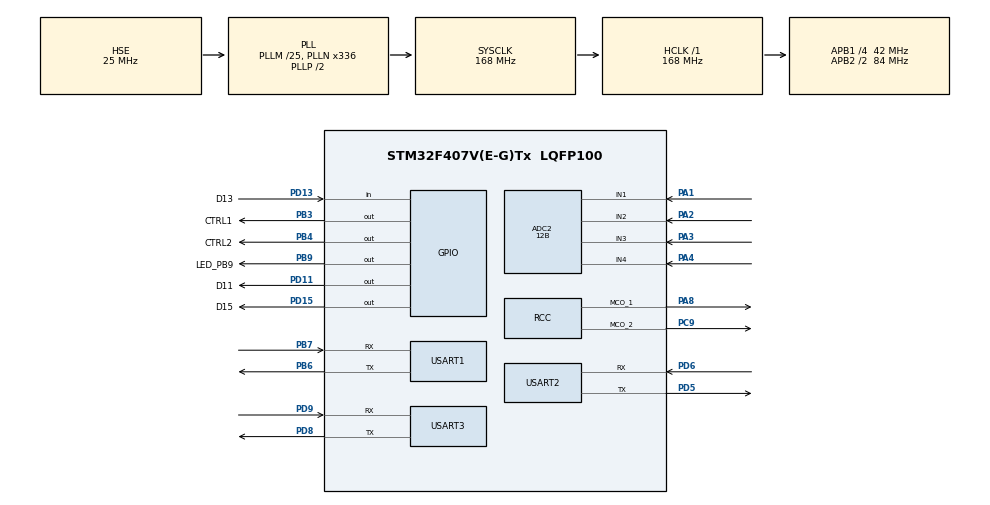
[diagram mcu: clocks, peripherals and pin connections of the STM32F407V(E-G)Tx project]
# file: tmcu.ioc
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ADC1.Channel-0\#ChannelRegularConversion=ADC_CHANNEL_TEMPSENSOR
ADC1.Channel-1\#ChannelInjectedConversion=ADC_CHANNEL_TEMPSENSOR
ADC1.Channel-2\#ChannelInjectedConversion=ADC_CHANNEL_VREFINT
ADC1.Channel-3\#ChannelInjectedConversion=ADC_CHANNEL_VBAT
ADC1.Channel-5\#ChannelInjectedConversion=ADC_CHANNEL_4
ADC1.ClockPrescaler=ADC_CLOCK_SYNC_PCLK_DIV8
ADC1.EOCSelection=ADC_EOC_SEQ_CONV
ADC1.ExternalTrigInjecConv=ADC_INJECTED_SOFTWARE_START
ADC1.InjNumberOfConversion=4
ADC1.InjectedConvMode=None
ADC1.InjectedOffset-1\#ChannelInjectedConversion=0
ADC1.InjectedOffset-2\#ChannelInjectedConversion=0
ADC1.InjectedOffset-3\#ChannelInjectedConversion=0
ADC1.InjectedOffset-5\#ChannelInjectedConversion=0
ADC1.NbrOfConversion=1
ADC1.NbrOfConversionFlag=1
ADC1.Rank-0\#ChannelRegularConversion=1
ADC1.Rank-1\#ChannelInjectedConversion=1
ADC1.Rank-2\#ChannelInjectedConversion=2
ADC1.Rank-3\#ChannelInjectedConversion=3
ADC1.Rank-5\#ChannelInjectedConversion=4
ADC1.SamplingTime-0\#ChannelRegularConversion=ADC_SAMPLETIME_3CYCLES
ADC1.SamplingTime-1\#ChannelInjectedConversion=ADC_SAMPLETIME_144CYCLES
ADC1.SamplingTime-2\#ChannelInjectedConversion=ADC_SAMPLETIME_144CYCLES
ADC1.SamplingTime-3\#ChannelInjectedConversion=ADC_SAMPLETIME_144CYCLES
ADC1.SamplingTime-5\#ChannelInjectedConversion=ADC_SAMPLETIME_144CYCLES
ADC1.ScanConvMode=ENABLE
ADC1.master=1
ADC2.Channel-4\#ChannelRegularConversion=ADC_CHANNEL_1
ADC2.Channel-5\#ChannelInjectedConversion=ADC_CHANNEL_1
ADC2.Channel-6\#ChannelInjectedConversion=ADC_CHANNEL_2
ADC2.Channel-7\#ChannelInjectedConversion=ADC_CHANNEL_3
ADC2.Channel-8\#ChannelInjectedConversion=ADC_CHANNEL_4
ADC2.ClockPrescaler=ADC_CLOCK_SYNC_PCLK_DIV8
ADC2.ContinuousConvMode=DISABLE
ADC2.DMAContinuousRequests=DISABLE
ADC2.DataAlign=ADC_DATAALIGN_RIGHT
ADC2.DiscontinuousConvMode=DISABLE
ADC2.EOCSelection=ADC_EOC_SEQ_CONV
ADC2.EnableAnalogWatchDog=false
ADC2.ExternalTrigConv=ADC_SOFTWARE_START
ADC2.ExternalTrigConvEdge=ADC_EXTERNALTRIGCONVEDGE_NONE
ADC2.ExternalTrigInjecConv=ADC_EXTERNALTRIGINJECCONV_T5_TRGO
ADC2.ExternalTrigInjecConvEdge=ADC_EXTERNALTRIGINJECCONVEDGE_RISING
ADC2.InjNumberOfConversion=4
ADC2.InjectedConvMode=None
ADC2.InjectedOffset-5\#ChannelInjectedConversion=0
ADC2.InjectedOffset-6\#ChannelInjectedConversion=0
ADC2.InjectedOffset-7\#ChannelInjectedConversion=0
ADC2.InjectedOffset-8\#ChannelInjectedConversion=0
ADC2.NbrOfConversion=1
ADC2.NbrOfConversionFlag=1
ADC2.Rank-4\#ChannelRegularConversion=1
ADC2.Rank-5\#ChannelInjectedConversion=1
ADC2.Rank-6\#ChannelInjectedConversion=2
ADC2.Rank-7\#ChannelInjectedConversion=3
ADC2.Rank-8\#ChannelInjectedConversion=4
ADC2.Resolution=ADC_RESOLUTION_12B
ADC2.SamplingTime-4\#ChannelRegularConversion=ADC_SAMPLETIME_3CYCLES
ADC2.SamplingTime-5\#ChannelInjectedConversion=ADC_SAMPLETIME_15CYCLES
ADC2.SamplingTime-6\#ChannelInjectedConversion=ADC_SAMPLETIME_15CYCLES
ADC2.SamplingTime-7\#ChannelInjectedConversion=ADC_SAMPLETIME_15CYCLES
ADC2.SamplingTime-8\#ChannelInjectedConversion=ADC_SAMPLETIME_15CYCLES
ADC2.ScanConvMode=ENABLE
IWDG.Prescaler=IWDG_PRESCALER_32
IWDG.Reload=2000
Mcu.Family=STM32F4
Mcu.Name=STM32F407V(E-G)Tx
Mcu.Package=LQFP100
NVIC.ADC_IRQn=true\:6\:0\:true\:false\:true
NVIC.PriorityGroup=NVIC_PRIORITYGROUP_3
NVIC.TIM5_IRQn=true\:4\:0\:true\:false\:true
NVIC.TIM6_DAC_IRQn=true\:5\:0\:true\:false\:true
NVIC.TIM7_IRQn=true\:4\:0\:true\:false\:true
NVIC.USART1_IRQn=true\:7\:0\:true\:false\:true
NVIC.USART2_IRQn=true\:7\:0\:true\:false\:true
NVIC.USART3_IRQn=true\:7\:0\:true\:false\:true
PA1.Signal=ADCx_IN1
PA2.Signal=ADCx_IN2
PA3.Signal=ADCx_IN3
PA4.Signal=ADCx_IN4
PA8.Mode=Clock-out-1
PA8.Signal=RCC_MCO_1
PB3.GPIO_Label=CTRL1
PB3.Signal=GPIO_Output
PB4.GPIO_Label=CTRL2
PB4.Signal=GPIO_Output
PB6.Mode=Asynchronous
PB6.Signal=USART1_TX
PB7.Mode=Asynchronous
PB7.Signal=USART1_RX
PB9.GPIO_Label=LED_PB9
PB9.Signal=GPIO_Output
PC9.Mode=Clock-out-2
PC9.Signal=RCC_MCO_2
PD11.GPIO_Label=D11
PD11.Signal=GPIO_Output
PD13.GPIO_Label=D13
PD13.Signal=GPIO_Input
PD15.GPIO_Label=D15
PD15.Signal=GPIO_Output
PD5.Mode=Asynchronous
PD5.Signal=USART2_TX
PD6.Mode=Asynchronous
PD6.Signal=USART2_RX
PD8.Mode=Asynchronous
PD8.Signal=USART3_TX
PD9.Mode=Asynchronous
PD9.Signal=USART3_RX
PH0-OSC_IN.Mode=HSE-External-Oscillator
PH0-OSC_IN.Signal=RCC_OSC_IN
PH1-OSC_OUT.Mode=HSE-External-Oscillator
PH1-OSC_OUT.Signal=RCC_OSC_OUT
ProjectManager.HeapSize=0x200
ProjectManager.StackSize=0x400
ProjectManager.TargetToolchain=MDK-ARM V5
RCC.48MHZClocksFreq_Value=48000000
RCC.AHBFreq_Value=168000000
RCC.APB1CLKDivider=RCC_HCLK_DIV4
RCC.APB1Freq_Value=42000000
RCC.APB1TimFreq_Value=84000000
RCC.APB2CLKDivider=RCC_HCLK_DIV2
RCC.APB2Freq_Value=84000000
RCC.APB2TimFreq_Value=168000000
RCC.CortexFreq_Value=168000000
RCC.HCLKFreq_Value=168000000
RCC.HSE_VALUE=25000000
RCC.HSI_VALUE=16000000
RCC.LSE_VALUE=32768
RCC.PLLM=25
RCC.PLLN=336
RCC.PLLQ=7
RCC.PLLSourceVirtual=RCC_PLLSOURCE_HSE
RCC.SYSCLKFreq_VALUE=168000000
RCC.SYSCLKSource=RCC_SYSCLKSOURCE_PLLCLK
RCC.VCOOutputFreq_Value=336000000
SH.ADCx_IN1.0=ADC2_IN1,IN1
SH.ADCx_IN2.0=ADC2_IN2,IN2
SH.ADCx_IN3.0=ADC2_IN3,IN3
SH.ADCx_IN4.0=ADC2_IN4,IN4
SH.ADCx_IN4.1=ADC1_IN4,IN4
TIM5.Period=125
TIM5.Prescaler=83
TIM5.TIM_MasterOutputTrigger=TIM_TRGO_UPDATE
TIM6.Period=10000
TIM6.Prescaler=8399
TIM6.TIM_MasterOutputTrigger=TIM_TRGO_UPDATE
TIM7.Period=1000
TIM7.Prescaler=8399
TIM7.TIM_MasterOutputTrigger=TIM_TRGO_UPDATE
USART1.VirtualMode=VM_ASYNC
USART2.VirtualMode=VM_ASYNC
USART3.VirtualMode=VM_ASYNC
VP_ADC1_TempSens_Input.Mode=IN-TempSens
VP_ADC1_Vbat_Input.Mode=IN-Vbat
VP_ADC1_Vref_Input.Mode=IN-Vrefint
VP_IWDG_VS_IWDG.Mode=IWDG_Activate
VP_RNG_VS_RNG.Mode=RNG_Activate
VP_TIM5_VS_ClockSourceINT.Mode=Internal
VP_TIM6_VS_ClockSourceINT.Mode=Enable_Timer
VP_TIM7_VS_ClockSourceINT.Mode=Enable_Timer
board=tmcu

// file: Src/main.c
/**
  ******************************************************************************
  * File Name          : main.c
  * Description        : Main program body
  ******************************************************************************
  ** This notice applies to any and all portions of this file
  * that are not between comment pairs USER CODE BEGIN and
  * USER CODE END. Other portions of this file, whether
  * inserted by the user or by software development tools
  * are owned by their respective copyright owners.
  *
  * COPYRIGHT(c) 2018 STMicroelectronics
  *
  * Redistribution and use in source and binary forms, with or without modification,
  * are permitted provided that the following conditions are met:
  *   1. Redistributions of source code must retain the above copyright notice,
  *      this list of conditions and the following disclaimer.
  *   2. Redistributions in binary form must reproduce the above copyright notice,
  *      this list of conditions and the following disclaimer in the documentation
  *      and/or other materials provided with the distribution.
  *   3. Neither the name of STMicroelectronics nor the names of its contributors
  *      may be used to endorse or promote products derived from this software
  *      without specific prior written permission.
  *
  * THIS SOFTWARE IS PROVIDED BY THE COPYRIGHT HOLDERS AND CONTRIBUTORS "AS IS"
  * AND ANY EXPRESS OR IMPLIED WARRANTIES, INCLUDING, BUT NOT LIMITED TO, THE
  * IMPLIED WARRANTIES OF MERCHANTABILITY AND FITNESS FOR A PARTICULAR PURPOSE ARE
  * DISCLAIMED. IN NO EVENT SHALL THE COPYRIGHT HOLDER OR CONTRIBUTORS BE LIABLE
  * FOR ANY DIRECT, INDIRECT, INCIDENTAL, SPECIAL, EXEMPLARY, OR CONSEQUENTIAL
  * DAMAGES (INCLUDING, BUT NOT LIMITED TO, PROCUREMENT OF SUBSTITUTE GOODS OR
  * SERVICES; LOSS OF USE, DATA, OR PROFITS; OR BUSINESS INTERRUPTION) HOWEVER
  * CAUSED AND ON ANY THEORY OF LIABILITY, WHETHER IN CONTRACT, STRICT LIABILITY,
  * OR TORT (INCLUDING NEGLIGENCE OR OTHERWISE) ARISING IN ANY WAY OUT OF THE USE
  * OF THIS SOFTWARE, EVEN IF ADVISED OF THE POSSIBILITY OF SUCH DAMAGE.
  *
  ******************************************************************************
  */
#include "main.h"
#include "stm32f4xx_hal.h"

/* USER CODE BEGIN Includes */
#include "action.h"
/* USER CODE END Includes */

ADC_HandleTypeDef hadc1;
ADC_HandleTypeDef hadc2;

IWDG_HandleTypeDef hiwdg;

RNG_HandleTypeDef hrng;

TIM_HandleTypeDef htim5;
TIM_HandleTypeDef htim6;
TIM_HandleTypeDef htim7;

UART_HandleTypeDef huart1;
UART_HandleTypeDef huart2;
UART_HandleTypeDef huart3;

/* USER CODE BEGIN PV */
/* Private variables ---------------------------------------------------------*/

/* USER CODE END PV */

void SystemClock_Config(void);
static void MX_GPIO_Init(void);
static void MX_ADC1_Init(void);
static void MX_ADC2_Init(void);
static void MX_IWDG_Init(void);
static void MX_RNG_Init(void);
static void MX_TIM5_Init(void);
static void MX_TIM6_Init(void);
static void MX_TIM7_Init(void);
static void MX_USART1_UART_Init(void);
static void MX_USART2_UART_Init(void);
static void MX_USART3_UART_Init(void);

/* USER CODE BEGIN PFP */
/* Private function prototypes -----------------------------------------------*/

/* USER CODE END PFP */

int main(void)
{

  /* MCU Configuration----------------------------------------------------------*/

  /* Reset of all peripherals, Initializes the Flash interface and the Systick. */
  HAL_Init();

  /* Configure the system clock */
  SystemClock_Config();

  /* Initialize all configured peripherals */
  MX_GPIO_Init();
  MX_ADC1_Init();
  MX_ADC2_Init();
//  MX_IWDG_Init();
  MX_RNG_Init();
  MX_TIM5_Init();
  MX_TIM6_Init();
  MX_TIM7_Init();
  MX_USART1_UART_Init();
  MX_USART2_UART_Init();
  MX_USART3_UART_Init();

  /* USER CODE BEGIN 2 */
	App_Init();
  /* USER CODE END 2 */

  /* Infinite loop */
  while (1)
  {
	App_Action();
  }

}

/** System Clock Configuration
*/
void SystemClock_Config(void)
{

  RCC_OscInitTypeDef RCC_OscInitStruct;
  RCC_ClkInitTypeDef RCC_ClkInitStruct;

    /**Configure the main internal regulator output voltage
    */
  __HAL_RCC_PWR_CLK_ENABLE();

  __HAL_PWR_VOLTAGESCALING_CONFIG(PWR_REGULATOR_VOLTAGE_SCALE1);

    /**Initializes the CPU, AHB and APB busses clocks
    */
  RCC_OscInitStruct.OscillatorType = RCC_OSCILLATORTYPE_HSI|RCC_OSCILLATORTYPE_LSI
                              |RCC_OSCILLATORTYPE_HSE;
  RCC_OscInitStruct.HSEState = RCC_HSE_ON;
  RCC_OscInitStruct.HSIState = RCC_HSI_ON;
  RCC_OscInitStruct.HSICalibrationValue = 16;
  RCC_OscInitStruct.LSIState = RCC_LSI_ON;
  RCC_OscInitStruct.PLL.PLLState = RCC_PLL_ON;
  RCC_OscInitStruct.PLL.PLLSource = RCC_PLLSOURCE_HSE;
  RCC_OscInitStruct.PLL.PLLM = 25;
  RCC_OscInitStruct.PLL.PLLN = 336;
  RCC_OscInitStruct.PLL.PLLP = RCC_PLLP_DIV2;
  RCC_OscInitStruct.PLL.PLLQ = 7;
  if (HAL_RCC_OscConfig(&RCC_OscInitStruct) != HAL_OK)
  {
    _Error_Handler(__FILE__, __LINE__);
  }

    /**Initializes the CPU, AHB and APB busses clocks
    */
  RCC_ClkInitStruct.ClockType = RCC_CLOCKTYPE_HCLK|RCC_CLOCKTYPE_SYSCLK
                              |RCC_CLOCKTYPE_PCLK1|RCC_CLOCKTYPE_PCLK2;
  RCC_ClkInitStruct.SYSCLKSource = RCC_SYSCLKSOURCE_PLLCLK;
  RCC_ClkInitStruct.AHBCLKDivider = RCC_SYSCLK_DIV1;
  RCC_ClkInitStruct.APB1CLKDivider = RCC_HCLK_DIV4;
  RCC_ClkInitStruct.APB2CLKDivider = RCC_HCLK_DIV2;

  if (HAL_RCC_ClockConfig(&RCC_ClkInitStruct, FLASH_LATENCY_5) != HAL_OK)
  {
    _Error_Handler(__FILE__, __LINE__);
  }

  HAL_RCC_MCOConfig(RCC_MCO1, RCC_MCO1SOURCE_HSI, RCC_MCODIV_1);

  HAL_RCC_MCOConfig(RCC_MCO2, RCC_MCO2SOURCE_SYSCLK, RCC_MCODIV_1);

    /**Configure the Systick interrupt time
    */
  HAL_SYSTICK_Config(HAL_RCC_GetHCLKFreq()/1000);

    /**Configure the Systick
    */
  HAL_SYSTICK_CLKSourceConfig(SYSTICK_CLKSOURCE_HCLK);

  /* SysTick_IRQn interrupt configuration */
  HAL_NVIC_SetPriority(SysTick_IRQn, 0, 0);
}

/* ADC1 init function */
static void MX_ADC1_Init(void)
{

  ADC_ChannelConfTypeDef sConfig;
  ADC_InjectionConfTypeDef sConfigInjected;

    /**Configure the global features of the ADC (Clock, Resolution, Data Alignment and number of conversion)
    */
  hadc1.Instance = ADC1;
  hadc1.Init.ClockPrescaler = ADC_CLOCK_SYNC_PCLK_DIV8;
  hadc1.Init.Resolution = ADC_RESOLUTION_12B;
  hadc1.Init.ScanConvMode = ENABLE;
  hadc1.Init.ContinuousConvMode = DISABLE;
  hadc1.Init.DiscontinuousConvMode = DISABLE;
  hadc1.Init.ExternalTrigConvEdge = ADC_EXTERNALTRIGCONVEDGE_NONE;
  hadc1.Init.ExternalTrigConv = ADC_SOFTWARE_START;
  hadc1.Init.DataAlign = ADC_DATAALIGN_RIGHT;
  hadc1.Init.NbrOfConversion = 1;
  hadc1.Init.DMAContinuousRequests = DISABLE;
  hadc1.Init.EOCSelection = ADC_EOC_SEQ_CONV;
  if (HAL_ADC_Init(&hadc1) != HAL_OK)
  {
    _Error_Handler(__FILE__, __LINE__);
  }

    /**Configure for the selected ADC regular channel its corresponding rank in the sequencer and its sample time.
    */
  sConfig.Channel = ADC_CHANNEL_TEMPSENSOR;
  sConfig.Rank = 1;
  sConfig.SamplingTime = ADC_SAMPLETIME_3CYCLES;
  if (HAL_ADC_ConfigChannel(&hadc1, &sConfig) != HAL_OK)
  {
    _Error_Handler(__FILE__, __LINE__);
  }

    /**Configures for the selected ADC injected channel its corresponding rank in the sequencer and its sample time
    */
  sConfigInjected.InjectedChannel = ADC_CHANNEL_TEMPSENSOR;
  sConfigInjected.InjectedRank = 1;
  sConfigInjected.InjectedNbrOfConversion = 4;
  sConfigInjected.InjectedSamplingTime = ADC_SAMPLETIME_144CYCLES;
  sConfigInjected.ExternalTrigInjecConvEdge = ADC_EXTERNALTRIGINJECCONVEDGE_NONE;
  sConfigInjected.ExternalTrigInjecConv = ADC_INJECTED_SOFTWARE_START;
  sConfigInjected.AutoInjectedConv = DISABLE;
  sConfigInjected.InjectedDiscontinuousConvMode = DISABLE;
  sConfigInjected.InjectedOffset = 0;
  if (HAL_ADCEx_InjectedConfigChannel(&hadc1, &sConfigInjected) != HAL_OK)
  {
    _Error_Handler(__FILE__, __LINE__);
  }

    /**Configures for the selected ADC injected channel its corresponding rank in the sequencer and its sample time
    */
  sConfigInjected.InjectedChannel = ADC_CHANNEL_VREFINT;
  sConfigInjected.InjectedRank = 2;
  if (HAL_ADCEx_InjectedConfigChannel(&hadc1, &sConfigInjected) != HAL_OK)
  {
    _Error_Handler(__FILE__, __LINE__);
  }

    /**Configures for the selected ADC injected channel its corresponding rank in the sequencer and its sample time
    */
  sConfigInjected.InjectedChannel = ADC_CHANNEL_VBAT;
  sConfigInjected.InjectedRank = 3;
  if (HAL_ADCEx_InjectedConfigChannel(&hadc1, &sConfigInjected) != HAL_OK)
  {
    _Error_Handler(__FILE__, __LINE__);
  }

    /**Configures for the selected ADC injected channel its corresponding rank in the sequencer and its sample time
    */
  sConfigInjected.InjectedChannel = ADC_CHANNEL_4;
  sConfigInjected.InjectedRank = 4;
  if (HAL_ADCEx_InjectedConfigChannel(&hadc1, &sConfigInjected) != HAL_OK)
  {
    _Error_Handler(__FILE__, __LINE__);
  }

}

/* ADC2 init function */
static void MX_ADC2_Init(void)
{

  ADC_ChannelConfTypeDef sConfig;
  ADC_InjectionConfTypeDef sConfigInjected;

    /**Configure the global features of the ADC (Clock, Resolution, Data Alignment and number of conversion)
    */
  hadc2.Instance = ADC2;
  hadc2.Init.ClockPrescaler = ADC_CLOCK_SYNC_PCLK_DIV8;
  hadc2.Init.Resolution = ADC_RESOLUTION_12B;
  hadc2.Init.ScanConvMode = ENABLE;
  hadc2.Init.ContinuousConvMode = DISABLE;
  hadc2.Init.DiscontinuousConvMode = DISABLE;
  hadc2.Init.ExternalTrigConvEdge = ADC_EXTERNALTRIGCONVEDGE_NONE;
  hadc2.Init.ExternalTrigConv = ADC_SOFTWARE_START;
  hadc2.Init.DataAlign = ADC_DATAALIGN_RIGHT;
  hadc2.Init.NbrOfConversion = 1;
  hadc2.Init.DMAContinuousRequests = DISABLE;
  hadc2.Init.EOCSelection = ADC_EOC_SEQ_CONV;
  if (HAL_ADC_Init(&hadc2) != HAL_OK)
  {
    _Error_Handler(__FILE__, __LINE__);
  }

    /**Configure for the selected ADC regular channel its corresponding rank in the sequencer and its sample time.
    */
  sConfig.Channel = ADC_CHANNEL_1;
  sConfig.Rank = 1;
  sConfig.SamplingTime = ADC_SAMPLETIME_3CYCLES;
  if (HAL_ADC_ConfigChannel(&hadc2, &sConfig) != HAL_OK)
  {
    _Error_Handler(__FILE__, __LINE__);
  }

    /**Configures for the selected ADC injected channel its corresponding rank in the sequencer and its sample time
    */
  sConfigInjected.InjectedChannel = ADC_CHANNEL_1;
  sConfigInjected.InjectedRank = 1;
  sConfigInjected.InjectedNbrOfConversion = 4;
  sConfigInjected.InjectedSamplingTime = ADC_SAMPLETIME_15CYCLES;
  sConfigInjected.ExternalTrigInjecConvEdge = ADC_EXTERNALTRIGINJECCONVEDGE_RISING;
  sConfigInjected.ExternalTrigInjecConv = ADC_EXTERNALTRIGINJECCONV_T5_TRGO;
  sConfigInjected.AutoInjectedConv = DISABLE;
  sConfigInjected.InjectedDiscontinuousConvMode = DISABLE;
  sConfigInjected.InjectedOffset = 0;
  if (HAL_ADCEx_InjectedConfigChannel(&hadc2, &sConfigInjected) != HAL_OK)
  {
    _Error_Handler(__FILE__, __LINE__);
  }

    /**Configures for the selected ADC injected channel its corresponding rank in the sequencer and its sample time
    */
  sConfigInjected.InjectedChannel = ADC_CHANNEL_2;
  sConfigInjected.InjectedRank = 2;
  if (HAL_ADCEx_InjectedConfigChannel(&hadc2, &sConfigInjected) != HAL_OK)
  {
    _Error_Handler(__FILE__, __LINE__);
  }

    /**Configures for the selected ADC injected channel its corresponding rank in the sequencer and its sample time
    */
  sConfigInjected.InjectedChannel = ADC_CHANNEL_3;
  sConfigInjected.InjectedRank = 3;
  if (HAL_ADCEx_InjectedConfigChannel(&hadc2, &sConfigInjected) != HAL_OK)
  {
    _Error_Handler(__FILE__, __LINE__);
  }

    /**Configures for the selected ADC injected channel its corresponding rank in the sequencer and its sample time
    */
  sConfigInjected.InjectedChannel = ADC_CHANNEL_4;
  sConfigInjected.InjectedRank = 4;
  if (HAL_ADCEx_InjectedConfigChannel(&hadc2, &sConfigInjected) != HAL_OK)
  {
    _Error_Handler(__FILE__, __LINE__);
  }

}

/* IWDG init function */
static void MX_IWDG_Init(void)
{

  hiwdg.Instance = IWDG;
  hiwdg.Init.Prescaler = IWDG_PRESCALER_32;
  hiwdg.Init.Reload = 2000;
  if (HAL_IWDG_Init(&hiwdg) != HAL_OK)
  {
    _Error_Handler(__FILE__, __LINE__);
  }

}

/* RNG init function */
static void MX_RNG_Init(void)
{

  hrng.Instance = RNG;
  if (HAL_RNG_Init(&hrng) != HAL_OK)
  {
    _Error_Handler(__FILE__, __LINE__);
  }

}

/* TIM5 init function */
static void MX_TIM5_Init(void)
{

  TIM_ClockConfigTypeDef sClockSourceConfig;
  TIM_MasterConfigTypeDef sMasterConfig;

  htim5.Instance = TIM5;
  htim5.Init.Prescaler = 83;
  htim5.Init.CounterMode = TIM_COUNTERMODE_UP;
  htim5.Init.Period = 125;
  htim5.Init.ClockDivision = TIM_CLOCKDIVISION_DIV1;
  if (HAL_TIM_Base_Init(&htim5) != HAL_OK)
  {
    _Error_Handler(__FILE__, __LINE__);
  }

  sClockSourceConfig.ClockSource = TIM_CLOCKSOURCE_INTERNAL;
  if (HAL_TIM_ConfigClockSource(&htim5, &sClockSourceConfig) != HAL_OK)
  {
    _Error_Handler(__FILE__, __LINE__);
  }

  sMasterConfig.MasterOutputTrigger = TIM_TRGO_UPDATE;
  sMasterConfig.MasterSlaveMode = TIM_MASTERSLAVEMODE_DISABLE;
  if (HAL_TIMEx_MasterConfigSynchronization(&htim5, &sMasterConfig) != HAL_OK)
  {
    _Error_Handler(__FILE__, __LINE__);
  }

}

/* TIM6 init function */
static void MX_TIM6_Init(void)
{

  TIM_MasterConfigTypeDef sMasterConfig;

  htim6.Instance = TIM6;
  htim6.Init.Prescaler = 8399;
  htim6.Init.CounterMode = TIM_COUNTERMODE_UP;
  htim6.Init.Period = 10000;
  if (HAL_TIM_Base_Init(&htim6) != HAL_OK)
  {
    _Error_Handler(__FILE__, __LINE__);
  }

  sMasterConfig.MasterOutputTrigger = TIM_TRGO_UPDATE;
  sMasterConfig.MasterSlaveMode = TIM_MASTERSLAVEMODE_DISABLE;
  if (HAL_TIMEx_MasterConfigSynchronization(&htim6, &sMasterConfig) != HAL_OK)
  {
    _Error_Handler(__FILE__, __LINE__);
  }

}

/* TIM7 init function */
static void MX_TIM7_Init(void)
{

  TIM_MasterConfigTypeDef sMasterConfig;

  htim7.Instance = TIM7;
  htim7.Init.Prescaler = 8399;
  htim7.Init.CounterMode = TIM_COUNTERMODE_UP;
  htim7.Init.Period = 1000;
  if (HAL_TIM_Base_Init(&htim7) != HAL_OK)
  {
    _Error_Handler(__FILE__, __LINE__);
  }

  sMasterConfig.MasterOutputTrigger = TIM_TRGO_UPDATE;
  sMasterConfig.MasterSlaveMode = TIM_MASTERSLAVEMODE_DISABLE;
  if (HAL_TIMEx_MasterConfigSynchronization(&htim7, &sMasterConfig) != HAL_OK)
  {
    _Error_Handler(__FILE__, __LINE__);
  }

}

/* USART1 init function */
static void MX_USART1_UART_Init(void)
{

  huart1.Instance = USART1;
  huart1.Init.BaudRate = 115200;
  huart1.Init.WordLength = UART_WORDLENGTH_8B;
  huart1.Init.StopBits = UART_STOPBITS_1;
  huart1.Init.Parity = UART_PARITY_NONE;
  huart1.Init.Mode = UART_MODE_TX_RX;
  huart1.Init.HwFlowCtl = UART_HWCONTROL_NONE;
  huart1.Init.OverSampling = UART_OVERSAMPLING_16;
  if (HAL_UART_Init(&huart1) != HAL_OK)
  {
    _Error_Handler(__FILE__, __LINE__);
  }

}

/* USART2 init function */
static void MX_USART2_UART_Init(void)
{

  huart2.Instance = USART2;
  huart2.Init.BaudRate = 115200;
  huart2.Init.WordLength = UART_WORDLENGTH_8B;
  huart2.Init.StopBits = UART_STOPBITS_1;
  huart2.Init.Parity = UART_PARITY_NONE;
  huart2.Init.Mode = UART_MODE_TX_RX;
  huart2.Init.HwFlowCtl = UART_HWCONTROL_NONE;
  huart2.Init.OverSampling = UART_OVERSAMPLING_16;
  if (HAL_UART_Init(&huart2) != HAL_OK)
  {
    _Error_Handler(__FILE__, __LINE__);
  }

}

/* USART3 init function */
static void MX_USART3_UART_Init(void)
{

  huart3.Instance = USART3;
  huart3.Init.BaudRate = 115200;
  huart3.Init.WordLength = UART_WORDLENGTH_8B;
  huart3.Init.StopBits = UART_STOPBITS_1;
  huart3.Init.Parity = UART_PARITY_NONE;
  huart3.Init.Mode = UART_MODE_TX_RX;
  huart3.Init.HwFlowCtl = UART_HWCONTROL_NONE;
  huart3.Init.OverSampling = UART_OVERSAMPLING_16;
  if (HAL_UART_Init(&huart3) != HAL_OK)
  {
    _Error_Handler(__FILE__, __LINE__);
  }

}

/** Configure pins as
        * Analog
        * Input
        * Output
        * EVENT_OUT
        * EXTI
     PC9   ------> RCC_MCO_2
     PA8   ------> RCC_MCO_1
*/
static void MX_GPIO_Init(void)
{

  GPIO_InitTypeDef GPIO_InitStruct;

  /* GPIO Ports Clock Enable */
  __HAL_RCC_GPIOH_CLK_ENABLE();
  __HAL_RCC_GPIOA_CLK_ENABLE();
  __HAL_RCC_GPIOD_CLK_ENABLE();
  __HAL_RCC_GPIOC_CLK_ENABLE();
  __HAL_RCC_GPIOB_CLK_ENABLE();

  /*Configure GPIO pin Output Level */
  HAL_GPIO_WritePin(GPIOD, D11_Pin|D15_Pin, GPIO_PIN_RESET);

  /*Configure GPIO pin Output Level */
  HAL_GPIO_WritePin(GPIOB, CTRL1_Pin|CTRL2_Pin|LED_PB9_Pin, GPIO_PIN_RESET);

  /*Configure GPIO pins : D11_Pin D15_Pin */
  GPIO_InitStruct.Pin = D11_Pin|D15_Pin;
  GPIO_InitStruct.Mode = GPIO_MODE_OUTPUT_PP;
  GPIO_InitStruct.Pull = GPIO_NOPULL;
  GPIO_InitStruct.Speed = GPIO_SPEED_FREQ_LOW;
  HAL_GPIO_Init(GPIOD, &GPIO_InitStruct);

  /*Configure GPIO pin : D13_Pin */
  GPIO_InitStruct.Pin = D13_Pin;
  GPIO_InitStruct.Mode = GPIO_MODE_INPUT;
  GPIO_InitStruct.Pull = GPIO_NOPULL;
  HAL_GPIO_Init(D13_GPIO_Port, &GPIO_InitStruct);

  /*Configure GPIO pin : PC9 */
  GPIO_InitStruct.Pin = GPIO_PIN_9;
  GPIO_InitStruct.Mode = GPIO_MODE_AF_PP;
  GPIO_InitStruct.Pull = GPIO_NOPULL;
  GPIO_InitStruct.Speed = GPIO_SPEED_FREQ_LOW;
  GPIO_InitStruct.Alternate = GPIO_AF0_MCO;
  HAL_GPIO_Init(GPIOC, &GPIO_InitStruct);

  /*Configure GPIO pin : PA8 */
  GPIO_InitStruct.Pin = GPIO_PIN_8;
  GPIO_InitStruct.Mode = GPIO_MODE_AF_PP;
  GPIO_InitStruct.Pull = GPIO_NOPULL;
  GPIO_InitStruct.Speed = GPIO_SPEED_FREQ_LOW;
  GPIO_InitStruct.Alternate = GPIO_AF0_MCO;
  HAL_GPIO_Init(GPIOA, &GPIO_InitStruct);

  /*Configure GPIO pins : CTRL1_Pin CTRL2_Pin LED_PB9_Pin */
  GPIO_InitStruct.Pin = CTRL1_Pin|CTRL2_Pin|LED_PB9_Pin;
  GPIO_InitStruct.Mode = GPIO_MODE_OUTPUT_PP;
  GPIO_InitStruct.Pull = GPIO_NOPULL;
  GPIO_InitStruct.Speed = GPIO_SPEED_FREQ_LOW;
  HAL_GPIO_Init(GPIOB, &GPIO_InitStruct);

}

void _Error_Handler(char * file, int line)
{
  while(1)
  {
  }
}

/************************ (C) COPYRIGHT STMicroelectronics *****END OF FILE****/
